# STM32F048xx register map
File version: 1.0
Registers are 32-bit, read-write, reset 0x0 unless marked. A register's access mark holds for its fields unless they carry their own. Offsets are from the block's base; [hi:lo] are bit positions; {n}, {i} and the like mark numbered series.

## SYSCFG — SysTem Configuration
Base 0x40010000
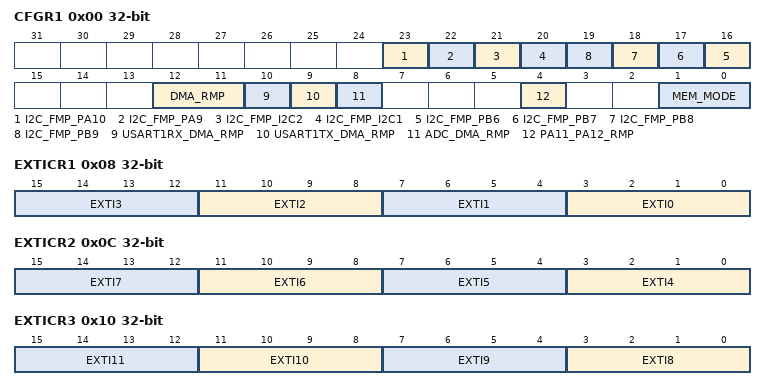
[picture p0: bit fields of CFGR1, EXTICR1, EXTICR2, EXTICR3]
0x00 CFGR1 — SYSCFG configuration register 1
  [23] I2C_FMP_PA10 — Enable Fast Mode Plus on PA10
  [22] I2C_FMP_PA9 — Enable Fast Mode Plus on PA9
  [21] I2C_FMP_I2C2 — Enable I2C2 Fast mode plus
  [20] I2C_FMP_I2C1 — Enable Fast Mode Plus on PB10, PB11, PF6 and PF7
  [n+10] I2C_FMP_PB{n} (n=6..9) — I2C PB{n} Fast mode plus
  [12:11] DMA_RMP — DMA remap mask
  [10] USART1RX_DMA_RMP — USART1 RX DMA remap
  [9] USART1TX_DMA_RMP — USART1 TX DMA remap
  [8] ADC_DMA_RMP — ADC DMA remap
    0=CH1 (ADC DMA request mapped on DMA channel 1U); 1=CH2 (ADC DMA request mapped on DMA channel 2U)
  [4] PA11_PA12_RMP — PA11 and PA12 remap on QFN28 and TSSOP20 packages
  [1:0] MEM_MODE — SYSCFG_Memory Remap Config
    0=FLASH (Main Flash memory mapped at 0x00000000); 1=SYSTEMFLASH (System Flash memory mapped at 0x00000000); 3=SRAM (Embedded SRAM mapped at 0x00000000)
0x08 EXTICR1 — SYSCFG external interrupt configuration register
  [4n+3:4n] EXTI{n} (n=0..3) — EXTI {n} configuration
0x0C EXTICR2 — SYSCFG external interrupt configuration register
  [4n-13:4n-16] EXTI{n} (n=4..7) — EXTI {n} configuration
0x10 EXTICR3 — SYSCFG external interrupt configuration register
  [4n-29:4n-32] EXTI{n} (n=8..11) — EXTI {n} configuration
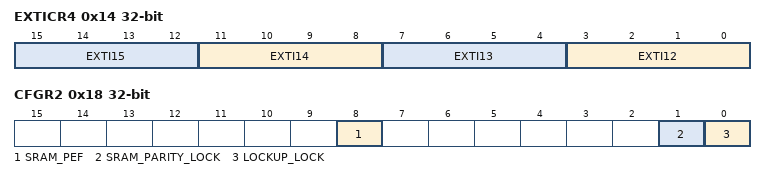
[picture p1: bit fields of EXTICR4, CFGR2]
0x14 EXTICR4 — SYSCFG external interrupt configuration register
  [4n-45:4n-48] EXTI{n} (n=12..15) — EXTI {n} configuration
0x18 CFGR2 — SYSCFG configuration register 2
  [8] SRAM_PEF — SRAM Parity error flag
  [1] SRAM_PARITY_LOCK — Enables and locks the SRAM_PARITY error signal with Break Input of TIMER1
  [0] LOCKUP_LOCK — Enables and locks the LOCKUP (Hardfault) output of CortexM0 with Break Input of TIMER1

## EXTI — External Interrupt/Event Controller
Base 0x40010400
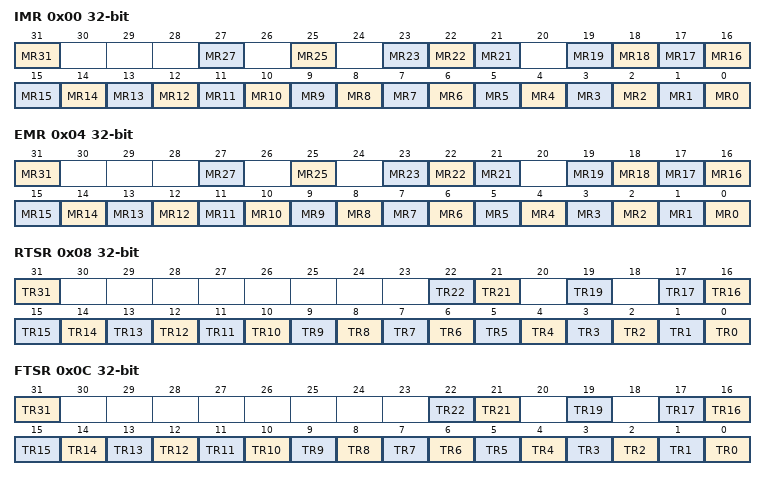
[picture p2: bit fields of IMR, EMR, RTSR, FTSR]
0x00 IMR — EXTI Interrupt mask register
  [31] MR31 — Interrupt Mask on line 31
  [27] MR27 — Interrupt Mask on line 27
  [25] MR25 — Interrupt Mask on line 25
  [23] MR23 — Interrupt Mask on line 23
  [22] MR22 — Interrupt Mask on line 22
  [21] MR21 — Interrupt Mask on line 21
  [n] MR{n} (n=0..19) — Interrupt Mask on line {n}
0x04 EMR — EXTI Event mask register
  [31] MR31 — Event Mask on line 31
  [27] MR27 — Event Mask on line 27
  [25] MR25 — Event Mask on line 25
  [23] MR23 — Event Mask on line 23
  [22] MR22 — Event Mask on line 22
  [21] MR21 — Event Mask on line 21
  [n] MR{n} (n=0..19) — Event Mask on line {n}
0x08 RTSR — EXTI Rising trigger selection register
  [31] TR31 — Rising trigger event configuration bit of line 31
  [22] TR22 — Rising trigger event configuration bit of line 22
  [21] TR21 — Rising trigger event configuration bit of line 21
  [19] TR19 — Rising trigger event configuration bit of line 19
  [n] TR{n} (n=0..17) — Rising trigger event configuration bit of line {n}
0x0C FTSR — EXTI Falling trigger selection register
  [31] TR31 — Falling trigger event configuration bit of line 31
  [22] TR22 — Falling trigger event configuration bit of line 22
  [21] TR21 — Falling trigger event configuration bit of line 21
  [19] TR19 — Falling trigger event configuration bit of line 19
  [n] TR{n} (n=0..17) — Falling trigger event configuration bit of line {n}
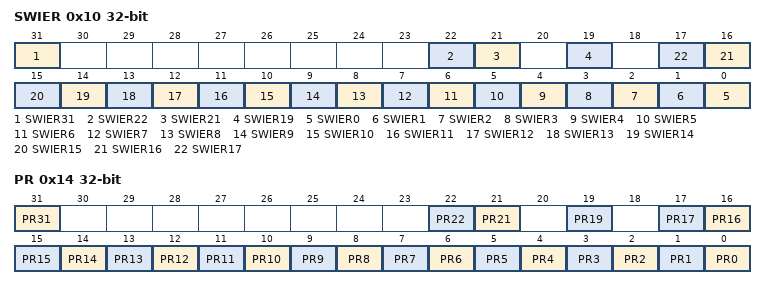
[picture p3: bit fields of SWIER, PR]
0x10 SWIER — EXTI Software interrupt event register
  [31] SWIER31 — Software Interrupt on line 31
  [22] SWIER22 — Software Interrupt on line 22
  [21] SWIER21 — Software Interrupt on line 21
  [19] SWIER19 — Software Interrupt on line 19
  [n] SWIER{n} (n=0..17) — Software Interrupt on line {n}
0x14 PR — EXTI Pending register
  [31] PR31 — Pending bit 31
  [22] PR22 — Pending bit 22
  [21] PR21 — Pending bit 21
  [19] PR19 — Pending bit 19
  [n] PR{n} (n=0..17) — Pending bit {n}

## ADC
Base 0x40012708
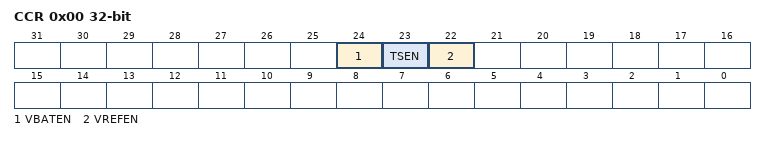
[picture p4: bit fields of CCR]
0x00 CCR — ADC common configuration register
  [24] VBATEN — ADC internal path to battery voltage enable
  [23] TSEN — ADC internal path to temperature sensor enable
  [22] VREFEN — ADC internal path to VrefInt enable
